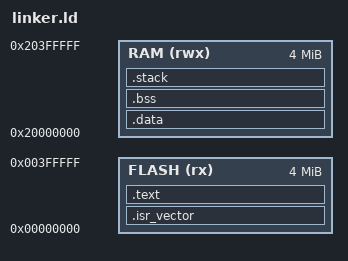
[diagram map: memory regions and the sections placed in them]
ENTRY(Reset_Handler)

MEMORY
{
    FLASH (rx)  : ORIGIN = 0x00000000, LENGTH = 4M
    RAM   (rwx) : ORIGIN = 0x20000000, LENGTH = 4M
}

SECTIONS
{
    .isr_vector :
    {
        . = ALIGN(4);
        KEEP(*(.isr_vector))
        . = ALIGN(4);
    } > FLASH

    .text :
    {
        . = ALIGN(4);
        *(.text.Reset_Handler)
        *(.text*)
        *(.rodata*)
        . = ALIGN(4);
        _etext = .;
    } > FLASH

    .data : AT(_etext)
    {
        . = ALIGN(4);
        _sdata = .;
        *(.data*)
        . = ALIGN(4);
        _edata = .;
    } > RAM

    _sidata = LOADADDR(.data);

    .bss (NOLOAD) :
    {
        . = ALIGN(4);
        _sbss = .;
        *(.bss*)
        *(COMMON)
        . = ALIGN(4);
        _ebss = .;
    } > RAM

    .stack (NOLOAD) :
    {
        . = ALIGN(8);
        _sstack = .;
        . += 16K;
        . = ALIGN(8);
        _estack = .;
    } > RAM

    /DISCARD/ :
    {
        *(.comment)
        *(.note*)
    }
}

ASSERT(_estack <= ORIGIN(RAM) + LENGTH(RAM), "RAM overflow")
